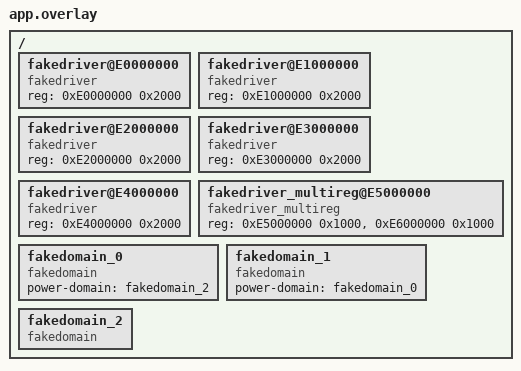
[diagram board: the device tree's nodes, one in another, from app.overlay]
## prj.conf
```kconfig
CONFIG_ZTEST=y
CONFIG_TEST_USERSPACE=y
CONFIG_PM_DEVICE=y
CONFIG_PM_DEVICE_RUNTIME=y
CONFIG_ZTEST_NEW_API=y
```

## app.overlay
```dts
/*
 * Copyright (c) 2020 Nordic Semiconductor ASA
 * Copyright (c) 2020 Intel Corporation
 *
 * SPDX-License-Identifier: Apache-2.0
 *
 * Application overlay for creating a fake device instance we
 * can use to test DEVICE_MMIO APIs, which get raw data about
 * memory ranges from DTS instances.
 *
 * Names in this file should be chosen in a way that won't conflict
 * with real-world devicetree nodes, to allow these tests to run on
 * (and be extended to test) real hardware.
 */

/ {
	#address-cells = <1>;
	#size-cells = <1>;

	fakedriver@E0000000 {
		compatible = "fakedriver";
		reg = <0xE0000000 0x2000>;
		status = "okay";
	};
	fakedriver@E1000000 {
		compatible = "fakedriver";
		reg = <0xE1000000 0x2000>;
		status = "okay";
	};
	fakedriver@E2000000 {
		compatible = "fakedriver";
		reg = <0xE2000000 0x2000>;
		status = "okay";
	};
	fakedriver@E3000000 {
		compatible = "fakedriver";
		reg = <0xE3000000 0x2000>;
		status = "okay";
	};
	fakedriver@E4000000 {
		compatible = "fakedriver";
		reg = <0xE4000000 0x2000>;
		status = "okay";
	};

	fakedriver_multireg@E5000000 {
		compatible = "fakedriver_multireg";
		reg = <0xE5000000 0x1000>,
		      <0xE6000000 0x1000>;
		reg-names = "chip",
			    "dale";
		status = "okay";
	};

	fakedomain_0: fakedomain_0 {
		compatible = "fakedomain";
		status = "okay";
		power-domain = <&fakedomain_2>;
	};

	fakedomain_1: fakedomain_1 {
		compatible = "fakedomain";
		status = "okay";
		power-domain = <&fakedomain_0>;
	};

	fakedomain_2: fakedomain_2 {
		compatible = "fakedomain";
		status = "okay";
	};
};
```

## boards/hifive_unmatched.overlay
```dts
/*
 * Copyright (c) 2020 Nordic Semiconductor ASA
 * Copyright (c) 2020 Intel Corporation
 *
 * SPDX-License-Identifier: Apache-2.0
 *
 * Application overlay for creating a fake device instance we
 * can use to test DEVICE_MMIO APIs, which get raw data about
 * memory ranges from DTS instances.
 *
 * Names in this file should be chosen in a way that won't conflict
 * with real-world devicetree nodes, to allow these tests to run on
 * (and be extended to test) real hardware.
 */

/ {
	fakedriver@E0000000 {
		compatible = "fakedriver";
		reg = <0x0 0xE0000000 0x0 0x2000>;
		status = "okay";
	};
	fakedriver@E1000000 {
		compatible = "fakedriver";
		reg = <0x0 0xE1000000 0x0 0x2000>;
		status = "okay";
	};
	fakedriver@E2000000 {
		compatible = "fakedriver";
		reg = <0x0 0xE2000000 0x0 0x2000>;
		status = "okay";
	};
	fakedriver@E3000000 {
		compatible = "fakedriver";
		reg = <0x0 0xE3000000 0x0 0x2000>;
		status = "okay";
	};
	fakedriver@E4000000 {
		compatible = "fakedriver";
		reg = <0x0 0xE4000000 0x0 0x2000>;
		status = "okay";
	};

	fakedriver_multireg@E5000000 {
		compatible = "fakedriver_multireg";
		reg = <0x0 0xE5000000 0x0 0x1000>,
		      <0x0 0xE6000000 0x0 0x1000>;
		reg-names = "chip",
			    "dale";
		status = "okay";
	};

	fakedomain_0: fakedomain_0 {
		compatible = "fakedomain";
		status = "okay";
		power-domain = <&fakedomain_2>;
	};

	fakedomain_1: fakedomain_1 {
		compatible = "fakedomain";
		status = "okay";
		power-domain = <&fakedomain_0>;
	};

	fakedomain_2: fakedomain_2 {
		compatible = "fakedomain";
		status = "okay";
	};
};
```

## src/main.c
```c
/*
 * Copyright (c) 2018 Intel Corporation
 *
 * SPDX-License-Identifier: Apache-2.0
 */

#include <zephyr/kernel.h>
#include <zephyr/device.h>
#include <zephyr/init.h>
#include <zephyr/ztest.h>
#include <zephyr/sys/printk.h>
#include <zephyr/linker/sections.h>
#include "abstract_driver.h"


#define DUMMY_PORT_1    "dummy"
#define DUMMY_PORT_2    "dummy_driver"
#define DUMMY_NOINIT    "dummy_noinit"
#define BAD_DRIVER	"bad_driver"

#define MY_DRIVER_A     "my_driver_A"
#define MY_DRIVER_B     "my_driver_B"

/* A device without init call */
DEVICE_DEFINE(dummy_noinit, DUMMY_NOINIT, NULL, NULL, NULL, NULL,
	      POST_KERNEL, CONFIG_KERNEL_INIT_PRIORITY_DEFAULT, NULL);

/**
 * @brief Test cases to verify device objects
 *
 * Verify zephyr device driver apis with different device types
 *
 * @defgroup kernel_device_tests Device
 *
 * @ingroup all_tests
 *
 * @{
 */

/**
 * @brief Test device object binding
 *
 * Validates device binding for an existing and a non-existing device object.
 * It creates a dummy_driver device object with basic init and configuration
 * information and validates its binding.
 *
 * Validates three kinds situations of driver object:
 * 1. A non-existing device object.
 * 2. An existing device object with basic init and configuration information.
 * 3. A failed init device object.
 *
 * @ingroup kernel_device_tests
 *
 * @see device_get_binding(), DEVICE_DEFINE()
 */
ZTEST(device, test_dummy_device)
{
	const struct device *dev;

	/* Validates device binding for a non-existing device object */
	dev = device_get_binding(DUMMY_PORT_1);
	zassert_is_null(dev);

	/* Validates device binding for an existing device object */
	dev = device_get_binding(DUMMY_PORT_2);
	zassert_not_null(dev);

	/* Validates device binding for an existing device object */
	dev = device_get_binding(DUMMY_NOINIT);
	zassert_not_null(dev);

	/* device_get_binding() returns false for device object
	 * with failed init.
	 */
	dev = device_get_binding(BAD_DRIVER);
	zassert_is_null(dev);
}

/**
 * @brief Test device binding for existing device
 *
 * Validates device binding for an existing device object.
 *
 * @see device_get_binding(), DEVICE_DEFINE()
 */
ZTEST_USER(device, test_dynamic_name)
{
	const struct device *mux;
	char name[sizeof(DUMMY_PORT_2)];

	snprintk(name, sizeof(name), "%s", DUMMY_PORT_2);
	mux = device_get_binding(name);
	zassert_true(mux != NULL);
}

/**
 * @brief Test device binding for non-existing device
 *
 * Validates binding of a random device driver(non-defined driver) named
 * "ANOTHER_BOGUS_NAME".
 *
 * @see device_get_binding(), DEVICE_DEFINE()
 */
ZTEST_USER(device, test_bogus_dynamic_name)
{
	const struct device *mux;
	char name[64];

	snprintk(name, sizeof(name), "ANOTHER_BOGUS_NAME");
	mux = device_get_binding(name);
	zassert_true(mux == NULL);
}

/**
 * @brief Test device binding for passing null name
 *
 * Validates device binding for device object when given dynamic name is null.
 *
 * @see device_get_binding(), DEVICE_DEFINE()
 */
ZTEST_USER(device, test_null_dynamic_name)
{
	/* Supplying a NULL dynamic name may trigger a SecureFault and
	 * lead to system crash in TrustZone enabled Non-Secure builds.
	 */
#if defined(CONFIG_USERSPACE) && !defined(CONFIG_TRUSTED_EXECUTION_NONSECURE)
	const struct device *mux;
	char *drv_name = NULL;

	mux = device_get_binding(drv_name);
	zassert_equal(mux, 0);
#else
	ztest_test_skip();
#endif
}

__pinned_bss
static struct init_record {
	bool pre_kernel;
	bool is_in_isr;
	bool is_pre_kernel;
	bool could_yield;
} init_records[4];

__pinned_data
static struct init_record *rp = init_records;

__pinned_func
static int add_init_record(bool pre_kernel)
{
	rp->pre_kernel = pre_kernel;
	rp->is_pre_kernel = k_is_pre_kernel();
	rp->is_in_isr = k_is_in_isr();
	rp->could_yield = k_can_yield();
	++rp;
	return 0;
}

__pinned_func
static int pre1_fn(void)
{
	return add_init_record(true);
}

__pinned_func
static int pre2_fn(void)
{
	return add_init_record(true);
}

static int post_fn(void)
{
	return add_init_record(false);
}

static int app_fn(void)
{
	return add_init_record(false);
}

SYS_INIT(pre1_fn, PRE_KERNEL_1, 0);
SYS_INIT(pre2_fn, PRE_KERNEL_2, 0);
SYS_INIT(post_fn, POST_KERNEL, 0);
SYS_INIT(app_fn, APPLICATION, 0);

/* This is an error case which driver initializes failed in SYS_INIT .*/
static int null_driver_init(void)
{
	return -EINVAL;
}

SYS_INIT(null_driver_init, POST_KERNEL, 0);

/**
 * @brief Test detection of initialization before kernel services available.
 *
 * Confirms check is correct.
 *
 * @see k_is_pre_kernel()
 */
ZTEST(device, test_pre_kernel_detection)
{
	struct init_record *rpe = rp;

	zassert_equal(rp - init_records, 4U,
		      "bad record count");
	rp = init_records;
	while ((rp < rpe) && rp->pre_kernel) {
		zassert_equal(rp->is_in_isr, false,
			      "rec %zu isr", rp - init_records);
		zassert_equal(rp->is_pre_kernel, true,
			      "rec %zu pre-kernel", rp - init_records);
		zassert_equal(rp->could_yield, false,
			      "rec %zu could-yield", rp - init_records);
		++rp;
	}
	zassert_equal(rp - init_records, 2U,
		      "bad pre-kernel count");

	while (rp < rpe) {
		zassert_equal(rp->is_in_isr, false,
			      "rec %zu isr", rp - init_records);
		zassert_equal(rp->is_pre_kernel, false,
			      "rec %zu post-kernel", rp - init_records);
		zassert_equal(rp->could_yield, true,
			      "rec %zu could-yield", rp - init_records);
		++rp;
	}
}

/**
 * @brief Test system device list query API.
 *
 * It queries the list of devices in the system, used to suspend or
 * resume the devices in PM applications.
 *
 * @see z_device_get_all_static()
 */
ZTEST(device, test_device_list)
{
	struct device const *devices;
	size_t devcount = z_device_get_all_static(&devices);

	zassert_false((devcount == 0));
}

static int sys_init_counter;

static int init_fn(void)
{
	sys_init_counter++;
	return 0;
}

SYS_INIT(init_fn, APPLICATION, 0);
SYS_INIT_NAMED(init1, init_fn, APPLICATION, 1);
SYS_INIT_NAMED(init2, init_fn, APPLICATION, 2);
SYS_INIT_NAMED(init3, init_fn, APPLICATION, 2);

ZTEST(device, test_sys_init_multiple)
{
	zassert_equal(sys_init_counter, 4, "");
}

/* this is for storing sequence during initialization */
extern int init_level_sequence[4];
extern int init_priority_sequence[4];
extern int init_sub_priority_sequence[3];
extern unsigned int seq_level_cnt;
extern unsigned int seq_priority_cnt;

/**
 * @brief Test initialization level for device driver instances
 *
 * @details After the defined device instances have initialized, we check the
 * sequence number that each driver stored during initialization. If the
 * sequence of initial level stored is corresponding with our expectation, it
 * means assigning the level for driver instance works.
 *
 * @ingroup kernel_device_tests
 */
ZTEST(device, test_device_init_level)
{
	bool seq_correct = true;

	/* we check if the stored executing sequence for different level is
	 * correct, and it should be 1, 2, 3, 4
	 */
	for (int i = 0; i < 4; i++) {
		if (init_level_sequence[i] != (i + 1)) {
			seq_correct = false;
		}
	}

	zassert_true((seq_correct == true),
			"init sequence is not correct");
}

/**
 * @brief Test initialization priorities for device driver instances
 *
 * @details After the defined device instances have initialized, we check the
 * sequence number that each driver stored during initialization. If the
 * sequence of initial priority stored is corresponding with our expectation, it
 * means assigning the priority for driver instance works.
 *
 * @ingroup kernel_device_tests
 */
ZTEST(device, test_device_init_priority)
{
	bool sequence_correct = true;

	/* we check if the stored pexecuting sequence for priority is correct,
	 * and it should be 1, 2, 3, 4
	 */
	for (int i = 0; i < 4; i++) {
		if (init_priority_sequence[i] != (i + 1)) {
			sequence_correct = false;
		}
	}

	zassert_true((sequence_correct == true),
			"init sequence is not correct");
}

/**
 * @brief Test initialization sub-priorities for device driver instances
 *
 * @details After the defined device instances have initialized, we check the
 * sequence number that each driver stored during initialization. If the
 * sequence of initial priority stored is corresponding with our expectation, it
 * means using the devicetree for sub-priority sorting works.
 *
 * @ingroup kernel_device_tests
 */
ZTEST(device, test_device_init_sub_priority)
{
	/* fakedomain_1 depends on fakedomain_0 which depends on fakedomain_2,
	 * therefore we require that the initialisation runs in the reverse order.
	 */
	zassert_equal(init_sub_priority_sequence[0], 1, "");
	zassert_equal(init_sub_priority_sequence[1], 2, "");
	zassert_equal(init_sub_priority_sequence[2], 0, "");
}

/**
 * @brief Test abstraction of device drivers with common functionalities
 *
 * @details Abstraction of device drivers with common functionalities
 * shall be provided as an intermediate interface between applications
 * and device drivers, where such interface is implemented by individual
 * device drivers. We verify this by following step:

 * 1. Define a subsystem api for drivers.
 * 2. Define and create two driver instances.
 * 3. Two drivers call the same subsystem API, and we verify that each
 * driver instance will call their own implementations.
 *
 * @ingroup kernel_device_tests
 */
ZTEST(device, test_abstraction_driver_common)
{
	const struct device *dev;
	int ret;
	int foo = 2;
	int bar = 1;
	unsigned int baz = 0;

	/* verify driver A API has called */
	dev = device_get_binding(MY_DRIVER_A);
	zassert_false((dev == NULL));

	ret = subsystem_do_this(dev, foo, bar);
	zassert_true(ret == (foo + bar), "common API do_this fail");

	subsystem_do_that(dev, &baz);
	zassert_true(baz == 1, "common API do_that fail");

	/* verify driver B API has called */
	dev = device_get_binding(MY_DRIVER_B);
	zassert_false((dev == NULL));

	ret = subsystem_do_this(dev, foo, bar);
	zassert_true(ret == (foo - bar), "common API do_this fail");

	subsystem_do_that(dev, &baz);
	zassert_true(baz == 2, "common API do_that fail");
}


/**
 * @}
 */

ZTEST_SUITE(device, NULL, NULL, NULL, NULL, NULL);
```

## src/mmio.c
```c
/*
 * Copyright (c) 2020 Intel Corporation
 *
 * SPDX-License-Identifier: Apache-2.0
 */

#include <zephyr/ztest.h>
#include <zephyr/device.h>

#define DT_DRV_COMPAT	fakedriver

/*
 * Driver with a single MMIO region to manage
 */

struct foo_single_dev_data {
	DEVICE_MMIO_RAM;
	int baz;
};

struct foo_single_dev_data foo0_data;

struct foo_single_config_info {
	DEVICE_MMIO_ROM;
};

const struct foo_single_config_info foo0_config = {
	DEVICE_MMIO_ROM_INIT(DT_DRV_INST(0)),
};

int foo_single_init(const struct device *dev)
{
	DEVICE_MMIO_MAP(dev, K_MEM_CACHE_NONE);

	return 0;
}

/* fake API pointer, we don't use it at all for this suite */
DEVICE_DEFINE(foo0, "foo0", foo_single_init, NULL,
		&foo0_data, &foo0_config,
		POST_KERNEL, CONFIG_KERNEL_INIT_PRIORITY_DEFAULT,
		(void *)0xDEADBEEF);

/**
 * @brief Test DEVICE_MMIO_* macros
 *
 * We show that we can make mapping calls and that the address returned by
 * DEVICE_MMIO_GET() is not NULL, indicating that the kernel mapped
 * stuff somewhere.
 *
 * We also perform some checks depending on configuration:
 * - If MMIO addresses are maintained in RAM, check that the ROM struct
 *   was populated correctly.
 * - If MMIO addresses are maintained in ROM, check that the DTS info,
 *   the ROM region, and the result of DEVICE_MMIO_GET() all
 *   point to the same address. We show that no extra memory is used in
 *   dev_data.
 *
 * @ingroup kernel_device_tests
 */
ZTEST(device, test_mmio_single)
{
	struct z_device_mmio_rom *rom;
	const struct device *dev = device_get_binding("foo0");
	mm_reg_t regs;

	zassert_not_null(dev, "null foo0");

	regs = DEVICE_MMIO_GET(dev);
	rom = DEVICE_MMIO_ROM_PTR(dev);

	/* A sign that something didn't get initialized, shouldn't ever
	 * be 0
	 */
	zassert_not_equal(regs, 0, "NULL regs");

#ifdef DEVICE_MMIO_IS_IN_RAM
	/* The config info should just contain the addr/size from DTS.
	 * The best we can check with 'regs' is that it's nonzero, as if
	 * an MMU is enabled, the kernel chooses the virtual address to
	 * place it at. We don't otherwise look at `regs`; other tests will
	 * prove that k_map() actually works.
	 */
	zassert_equal(rom->phys_addr, DT_INST_REG_ADDR(0), "bad phys_addr");
	zassert_equal(rom->size, DT_INST_REG_SIZE(0), "bad size");
#else
	/* Config info contains base address, which should be the base
	 * address from DTS, and regs should have the same value.
	 * In this configuration dev_data has nothing mmio-related in it
	 */
	zassert_equal(rom->addr, DT_INST_REG_ADDR(0), "bad addr");
	zassert_equal(regs, rom->addr, "bad regs");
	/* Just the baz member */
	zassert_equal(sizeof(struct foo_single_dev_data), sizeof(int),
		      "too big foo_single_dev_data");
#endif
}

/*
 * Driver with multiple MMIO regions to manage
 */

struct foo_mult_dev_data {
	int baz;

	DEVICE_MMIO_NAMED_RAM(corge);
	DEVICE_MMIO_NAMED_RAM(grault);
};

struct foo_mult_dev_data foo12_data;

struct foo_mult_config_info {
	DEVICE_MMIO_NAMED_ROM(corge);
	DEVICE_MMIO_NAMED_ROM(grault);
};

const struct foo_mult_config_info foo12_config = {
	DEVICE_MMIO_NAMED_ROM_INIT(corge, DT_DRV_INST(1)),
	DEVICE_MMIO_NAMED_ROM_INIT(grault, DT_DRV_INST(2))
};

#define DEV_DATA(dev)	((struct foo_mult_dev_data *)((dev)->data))
#define DEV_CFG(dev)	((struct foo_mult_config_info *)((dev)->config))

int foo_mult_init(const struct device *dev)
{
	DEVICE_MMIO_NAMED_MAP(dev, corge, K_MEM_CACHE_NONE);
	DEVICE_MMIO_NAMED_MAP(dev, grault, K_MEM_CACHE_NONE);

	return 0;
}

DEVICE_DEFINE(foo12, "foo12", foo_mult_init, NULL,
		&foo12_data, &foo12_config,
		POST_KERNEL, CONFIG_KERNEL_INIT_PRIORITY_DEFAULT,
		(void *)0xDEADBEEF);

/**
 * @brief Test DEVICE_MMIO_NAMED_* macros
 *
 * We show that we can make mapping calls and that the address returned by
 * DEVICE_MMIO_NAMED_GET() is not NULL, indicating that the kernel mapped
 * stuff somewhere.
 *
 * We show that this works for a device instance that has two named regions,
 * 'corge' and 'grault' that respectively come from DTS instances 1 and 2.
 *
 * We also perform some checks depending on configuration:
 * - If MMIO addresses are maintained in RAM, check that the ROM struct
 *   was populated correctly.
 * - If MMIO addresses are maintained in ROM, check that the DTS info,
 *   the ROM region, and the result of DEVICE_MMIO_NAMED_GET() all
 *   point to the same address. We show that no extra memory is used in
 *   dev_data.
 *
 * @ingroup kernel_device_tests
 */
ZTEST(device, test_mmio_multiple)
{
	/* See comments for test_mmio_single */
	const struct device *dev = device_get_binding("foo12");
	mm_reg_t regs_corge, regs_grault;
	const struct z_device_mmio_rom *rom_corge, *rom_grault;

	zassert_not_null(dev, "null foo12");

	regs_corge = DEVICE_MMIO_NAMED_GET(dev, corge);
	regs_grault = DEVICE_MMIO_NAMED_GET(dev, grault);
	rom_corge = DEVICE_MMIO_NAMED_ROM_PTR(dev, corge);
	rom_grault = DEVICE_MMIO_NAMED_ROM_PTR(dev, grault);

	zassert_not_equal(regs_corge, 0, "bad regs_corge");
	zassert_not_equal(regs_grault, 0, "bad regs_grault");

#ifdef DEVICE_MMIO_IS_IN_RAM
	zassert_equal(rom_corge->phys_addr, DT_INST_REG_ADDR(1),
		      "bad phys_addr (corge)");
	zassert_equal(rom_corge->size, DT_INST_REG_SIZE(1),
		      "bad size (corge)");
	zassert_equal(rom_grault->phys_addr, DT_INST_REG_ADDR(2),
		      "bad phys_addr (grault)");
	zassert_equal(rom_grault->size, DT_INST_REG_SIZE(2),
		      "bad size (grault)");
#else
	zassert_equal(rom_corge->addr, DT_INST_REG_ADDR(1),
		      "bad addr (corge)");
	zassert_equal(regs_corge, rom_corge->addr, "bad regs (corge)");
	zassert_equal(rom_grault->addr, DT_INST_REG_ADDR(2),
		      "bad addr (grault)");
	zassert_equal(regs_grault, rom_grault->addr, "bad regs (grault)");
	zassert_equal(sizeof(struct foo_mult_dev_data), sizeof(int),
		      "too big foo_mult_dev_data");
#endif
}

/*
 * Not using driver model, toplevel definition
 */
DEVICE_MMIO_TOPLEVEL(foo3, DT_DRV_INST(3));
DEVICE_MMIO_TOPLEVEL_STATIC(foo4, DT_DRV_INST(4));

/**
 * @brief Test DEVICE_MMIO_TOPLEVEL_* macros
 *
 * We show that we can make mapping calls and that the address returned by
 * DEVICE_MMIO_TOPLEVEL_GET() is not NULL, indicating that the kernel mapped
 * stuff somewhere.
 *
 * We do this for two different MMIO toplevel instances; one declared
 * statically and one not.
 *
 * We also perform some checks depending on configuration:
 * - If MMIO addresses are maintained in RAM, check that the ROM struct
 *   was populated correctly.
 * - If MMIO addresses are maintained in ROM, check that the DTS info,
 *   the ROM region, and the result of DEVICE_MMIO_TOPLEVEL_GET() all
 *   point to the same address
 *
 * @ingroup kernel_device_tests
 */
ZTEST(device, test_mmio_toplevel)
{
	mm_reg_t regs_foo3, regs_foo4;
	const struct z_device_mmio_rom *rom_foo3, *rom_foo4;

	DEVICE_MMIO_TOPLEVEL_MAP(foo3, K_MEM_CACHE_NONE);
	DEVICE_MMIO_TOPLEVEL_MAP(foo4, K_MEM_CACHE_NONE);

	regs_foo3 = DEVICE_MMIO_TOPLEVEL_GET(foo3);
	regs_foo4 = DEVICE_MMIO_TOPLEVEL_GET(foo4);
	rom_foo3 = DEVICE_MMIO_TOPLEVEL_ROM_PTR(foo3);
	rom_foo4 = DEVICE_MMIO_TOPLEVEL_ROM_PTR(foo4);

	zassert_not_equal(regs_foo3, 0, "bad regs_corge");
	zassert_not_equal(regs_foo4, 0, "bad regs_grault");

#ifdef DEVICE_MMIO_IS_IN_RAM
	zassert_equal(rom_foo3->phys_addr, DT_INST_REG_ADDR(3),
		      "bad phys_addr (foo3)");
	zassert_equal(rom_foo3->size, DT_INST_REG_SIZE(3),
		      "bad size (foo3)");
	zassert_equal(rom_foo4->phys_addr, DT_INST_REG_ADDR(4),
		      "bad phys_addr (foo4)");
	zassert_equal(rom_foo4->size, DT_INST_REG_SIZE(4),
		      "bad size (foo4)");
#else
	zassert_equal(rom_foo3->addr, DT_INST_REG_ADDR(3),
		      "bad addr (foo3)");
	zassert_equal(regs_foo3, rom_foo3->addr, "bad regs (foo3)");
	zassert_equal(rom_foo4->addr, DT_INST_REG_ADDR(4),
		      "bad addr (foo4)");
	zassert_equal(regs_foo4, rom_foo4->addr, "bad regs (foo4)");
#endif
}

/**
 * @brief device_map() test
 *
 * Show that device_map() populates a memory address. We don't do anything else;
 * tests for k_map() will prove that virtual memory mapping actually works.
 */
ZTEST(device, test_mmio_device_map)
{
#ifdef DEVICE_MMIO_IS_IN_RAM
	mm_reg_t regs = 0;

	device_map(&regs, 0xF0000000, 0x1000, K_MEM_CACHE_NONE);

	zassert_not_equal(regs, 0, "bad regs");
#else
	ztest_test_skip();
#endif
}
```

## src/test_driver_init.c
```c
/*
 * Copyright (c) 2020 Intel Corporation
 *
 * SPDX-License-Identifier: Apache-2.0
 */

#include <zephyr/kernel.h>
#include <zephyr/device.h>
#include <zephyr/init.h>
#include <zephyr/ztest.h>
#include <zephyr/linker/sections.h>


/**
 * @brief Test cases to device driver initialization
 *
 */

#define MY_DRIVER_LV_1    "my_driver_level_1"
#define MY_DRIVER_LV_2    "my_driver_level_2"
#define MY_DRIVER_LV_3    "my_driver_level_3"
#define MY_DRIVER_LV_4    "my_driver_level_4"
#define MY_DRIVER_PRI_1    "my_driver_priority_1"
#define MY_DRIVER_PRI_2    "my_driver_priority_2"
#define MY_DRIVER_PRI_3    "my_driver_priority_3"
#define MY_DRIVER_PRI_4    "my_driver_priority_4"

#define LEVEL_PRE_KERNEL_1	1
#define LEVEL_PRE_KERNEL_2	2
#define LEVEL_POST_KERNEL	3
#define LEVEL_APPLICATION	4

#define PRIORITY_1	1
#define PRIORITY_2	2
#define PRIORITY_3	3
#define PRIORITY_4	4


/* this is for storing sequence during initialization */
__pinned_bss int init_level_sequence[4] = {0};
__pinned_bss int init_priority_sequence[4] = {0};
__pinned_bss int init_sub_priority_sequence[3] = {0};
__pinned_bss unsigned int seq_level_cnt;
__pinned_bss unsigned int seq_priority_cnt;
__pinned_bss unsigned int seq_sub_priority_cnt;

/* define driver type 1: for testing initialize levels and priorities */
typedef int (*my_api_configure_t)(const struct device *dev, int dev_config);

struct my_driver_api {
	my_api_configure_t configure;
};

static int my_configure(const struct device *dev, int config)
{
	return 0;
}

static const struct my_driver_api funcs_my_drivers = {
	.configure = my_configure,
};

/* driver init function of testing level */
__pinned_func
static int my_driver_lv_1_init(const struct device *dev)
{
	init_level_sequence[seq_level_cnt] = LEVEL_PRE_KERNEL_1;
	seq_level_cnt++;

	return 0;
}

__pinned_func
static int my_driver_lv_2_init(const struct device *dev)
{
	init_level_sequence[seq_level_cnt] = LEVEL_PRE_KERNEL_2;
	seq_level_cnt++;

	return 0;
}

static int my_driver_lv_3_init(const struct device *dev)
{
	init_level_sequence[seq_level_cnt] = LEVEL_POST_KERNEL;
	seq_level_cnt++;

	return 0;
}

static int my_driver_lv_4_init(const struct device *dev)
{
	init_level_sequence[seq_level_cnt] = LEVEL_APPLICATION;
	seq_level_cnt++;

	return 0;
}

/* driver init function of testing priority */
static int my_driver_pri_1_init(const struct device *dev)
{
	init_priority_sequence[seq_priority_cnt] = PRIORITY_1;
	seq_priority_cnt++;

	return 0;
}

static int my_driver_pri_2_init(const struct device *dev)
{
	init_priority_sequence[seq_priority_cnt] = PRIORITY_2;
	seq_priority_cnt++;

	return 0;
}

static int my_driver_pri_3_init(const struct device *dev)
{
	init_priority_sequence[seq_priority_cnt] = PRIORITY_3;
	seq_priority_cnt++;

	return 0;
}

static int my_driver_pri_4_init(const struct device *dev)
{
	init_priority_sequence[seq_priority_cnt] = PRIORITY_4;
	seq_priority_cnt++;

	return 0;
}

/* driver init function of testing sub_priority */
static int my_driver_sub_pri_0_init(const struct device *dev)
{
	init_sub_priority_sequence[0] = seq_sub_priority_cnt++;

	return 0;
}

static int my_driver_sub_pri_1_init(const struct device *dev)
{
	init_sub_priority_sequence[1] = seq_sub_priority_cnt++;

	return 0;
}

static int my_driver_sub_pri_2_init(const struct device *dev)
{
	init_sub_priority_sequence[2] = seq_sub_priority_cnt++;

	return 0;
}

/**
 * @brief Test providing control device driver initialization order
 *
 * @details Test that kernel shall provide control over device driver
 * initialization order, using initialization level and priority for each
 * instance. We use DEVICE_DEFINE to define device instances and set
 * it's level and priority here, then we run check function later after
 * all of this instance finish their initialization.
 *
 * @ingroup kernel_device_tests
 */
DEVICE_DEFINE(my_driver_level_1, MY_DRIVER_LV_1, &my_driver_lv_1_init,
		NULL, NULL, NULL, PRE_KERNEL_1,
		CONFIG_KERNEL_INIT_PRIORITY_DEFAULT, &funcs_my_drivers);

DEVICE_DEFINE(my_driver_level_2, MY_DRIVER_LV_2, &my_driver_lv_2_init,
		NULL, NULL, NULL, PRE_KERNEL_2,
		CONFIG_KERNEL_INIT_PRIORITY_DEFAULT, &funcs_my_drivers);

DEVICE_DEFINE(my_driver_level_3, MY_DRIVER_LV_3, &my_driver_lv_3_init,
		NULL, NULL, NULL, POST_KERNEL,
		CONFIG_KERNEL_INIT_PRIORITY_DEFAULT, &funcs_my_drivers);

DEVICE_DEFINE(my_driver_level_4, MY_DRIVER_LV_4, &my_driver_lv_4_init,
		NULL, NULL, NULL, APPLICATION,
		CONFIG_KERNEL_INIT_PRIORITY_DEFAULT, &funcs_my_drivers);

/* We use priority value of 20 to create a possible sorting conflict with
 * priority value of 2.  So if the linker sorting isn't working correctly
 * we'll find out.
 */
DEVICE_DEFINE(my_driver_priority_4, MY_DRIVER_PRI_4,
		&my_driver_pri_4_init, NULL, NULL, NULL, POST_KERNEL, 20,
		&funcs_my_drivers);

DEVICE_DEFINE(my_driver_priority_1, MY_DRIVER_PRI_1,
		&my_driver_pri_1_init, NULL, NULL, NULL, POST_KERNEL, 1,
		&funcs_my_drivers);

DEVICE_DEFINE(my_driver_priority_2, MY_DRIVER_PRI_2,
		&my_driver_pri_2_init, NULL, NULL, NULL, POST_KERNEL, 2,
		&funcs_my_drivers);

DEVICE_DEFINE(my_driver_priority_3, MY_DRIVER_PRI_3,
		&my_driver_pri_3_init, NULL, NULL, NULL, POST_KERNEL, 3,
		&funcs_my_drivers);

/* Create several devices at the same init priority that depend on each
 * other in devicetree so that we can validate linker sorting.
 */
DEVICE_DT_DEFINE(DT_NODELABEL(fakedomain_0), my_driver_sub_pri_0_init,
		NULL, NULL, NULL, APPLICATION, 33, NULL);
DEVICE_DT_DEFINE(DT_NODELABEL(fakedomain_1), my_driver_sub_pri_1_init,
		NULL, NULL, NULL, APPLICATION, 33, NULL);
DEVICE_DT_DEFINE(DT_NODELABEL(fakedomain_2), my_driver_sub_pri_2_init,
		NULL, NULL, NULL, APPLICATION, 33, NULL);
```
